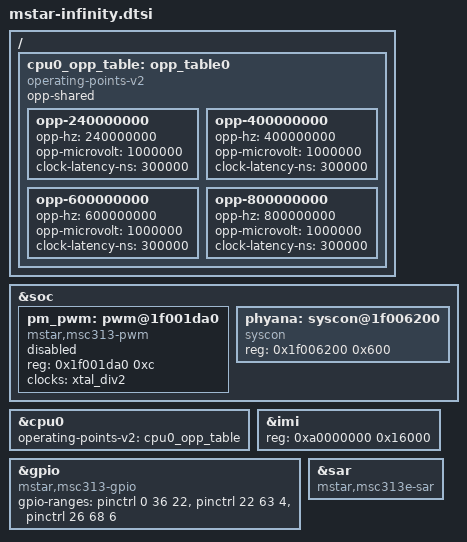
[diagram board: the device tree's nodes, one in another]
// SPDX-License-Identifier: GPL-2.0-or-later
/*
 * Copyright (c) 2020 thingy.jp.
 * Author: Daniel Palmer <daniel@thingy.jp>
 */

#include "mstar-v7.dtsi"

#include <dt-bindings/gpio/msc313-gpio.h>

/ {
	cpu0_opp_table: opp_table0 {
		compatible = "operating-points-v2";
		opp-shared;

		opp-240000000 {
			opp-hz = /bits/ 64 <240000000>;
			opp-microvolt = <1000000>;
			clock-latency-ns = <300000>;
		};

		opp-400000000 {
			opp-hz = /bits/ 64 <400000000>;
			opp-microvolt = <1000000>;
			clock-latency-ns = <300000>;
		};
		opp-600000000 {
			opp-hz = /bits/ 64 <600000000>;
			opp-microvolt = <1000000>;
			clock-latency-ns = <300000>;
		};

		opp-800000000 {
			opp-hz = /bits/ 64 <800000000>;
			opp-microvolt = <1000000>;
			clock-latency-ns = <300000>;
		};
	};
};

&soc {
	pm_pwm: pwm@1f001da0 {
		compatible = "mstar,msc313-pwm";
		reg = <0x1f001da0 0xc>;
		#pwm-cells = <2>;
		clocks = <&xtal_div2>;
		status = "disabled";
	};

	phyana: syscon@1f006200 {
		/* albany ethernet phy
	         * 0x1f006200
		 * 0x1f006400
		 * 0x1f006600
		 */
		compatible = "syscon";
		reg = <0x1f006200 0x600>;
	};
};

&cpu0 {
	operating-points-v2 = <&cpu0_opp_table>;
};

&imi {
	reg = <0xa0000000 0x16000>;
};

&gpio {
	compatible = "mstar,msc313-gpio";
	gpio-ranges = <&pinctrl 0 36 22>,
		      <&pinctrl 22 63 4>,
		      <&pinctrl 26 68 6>;
	status = "okay";
};

&sar {
	compatible = "mstar,msc313e-sar";
};
